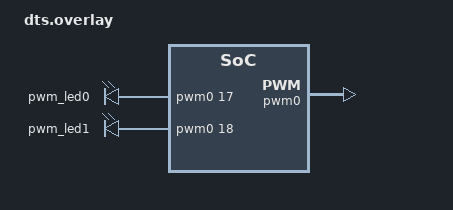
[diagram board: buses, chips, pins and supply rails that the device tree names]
/ {
	
	pwmleds {
		compatible = "pwm-leds";
		pwm_led0: pwm_led_0 {
			pwms = <&pwm0 17>;
		};
		pwm_led1: pwm_led_1 {
			pwms = <&pwm0 18>;			
		};
		
	};
	
	
	/* These aliases are provided for compatibility with samples */
	aliases {
		led0 = &led0;
		led1 = &led1;
		led2 = &led2;
		led3 = &led3;
		pwm-led0 = &pwm_led0;
		pwm-led1 = &pwm_led1;
		sw0 = &button0;
		sw1 = &button1;
		sw2 = &button2;
		sw3 = &button3;
		bootloader-led0 = &led0;
	};
};
	
	&pwm0 {
		status = "okay";
		ch0-pin = <17>;
		ch0-inverted;
		ch1-pin = <18>;
		ch1-inverted;
	};
	

